VERSION ""

NS_ :

BS_:

BU_: MAHLE_Device_2 Vehicle MAHLE_Device
VAL_TABLE_ vtEv_ACTUAL_VOLTAGE 1023 "Not Available" 1022 "Error Indicator" ;
VAL_TABLE_ vtEv_8bits 254 "Error Indicator" 255 "Not Available / Not Requested" 250 "Valid Range" ;
VAL_TABLE_ vtEv_Failure_Status 1 "True" 0 "False" ;
VAL_TABLE_ vtEv_Voltage_Range 3 "Invalid" 2 "48 V product version" 1 "24 V product version" 0 "12 V Product Version" ;
VAL_TABLE_ vtEv_Speed_Values 1023 "Invalid" 0 "Motor stops (Sleep_Mode)" ;
VAL_TABLE_ Types_DM 19 "DM19" 18 "DM18" 17 "DM17" 16 "DM16" 15 "DM15" 14 "DM14" 13 "DM13" 12 "DM12" 11 "DM11" 10 "DM10" 8 "DM8" 7 "DM7" 6 "DM6" 5 "DM5" 4 "DM4" 3 "DM3" 2 "DM2" 1 "DM1" 0 "CHOOSE" ;
VAL_TABLE_ TYPE_OF_CTS 0 "CHOOSE" 255 "ABORT" 19 "EOM" 17 "PROCEED" ;
VAL_TABLE_ Priority_values 7 "SEVEN" 6 "SIX" 5 "FIVE" 4 "FOUR" 3 "THREE" 2 "TWO" 1 "ONE" 0 "ZERO" ;

BO_ 3221225472 VECTOR__INDEPENDENT_SIG_MSG: 0 Vector__XXX
 SG_ EOL_STATUS_SW_VERSION : 0|16@1+ (1,0) [0|65535] "" Vector__XXX
 SG_ EOL_STATUS_CAN_ID : 0|2@1+ (1,0) [0|3] "" Vector__XXX
 SG_ EOL_STATUS_NTC_TEMP : 0|8@1+ (1,0) [0|255] "" Vector__XXX
 SG_ EOL_STATUS_DCLINK : 0|12@1+ (1,0) [0|4095] "" Vector__XXX
 SG_ EOL_STATUS_VBAT : 0|12@1+ (1,0) [0|4095] "" Vector__XXX
 SG_ EOL_STATUS_SW_VERSION : 0|16@1+ (1,0) [0|65535] "" Vector__XXX
 SG_ EOL_STATUS_CAN_ID : 0|2@1+ (1,0) [0|3] "" Vector__XXX
 SG_ EOL_STATUS_NTC_TEMP : 0|8@1+ (1,0) [0|255] "" Vector__XXX
 SG_ EOL_STATUS_DCLINK : 0|12@1+ (1,0) [0|4095] "" Vector__XXX
 SG_ EOL_STATUS_VBAT : 0|12@1+ (1,0) [0|4095] "" Vector__XXX
 SG_ EOL_STATUS_SW_VERSION : 0|16@1+ (1,0) [0|65535] "" Vector__XXX
 SG_ EOL_STATUS_CAN_ID : 0|2@1+ (1,0) [0|3] "" Vector__XXX
 SG_ EOL_STATUS_NTC_TEMP : 0|8@1+ (1,0) [0|255] "" Vector__XXX
 SG_ EOL_STATUS_DCLINK : 0|12@1+ (1,0) [0|4095] "" Vector__XXX
 SG_ EOL_STATUS_VBAT : 0|12@1+ (1,0) [0|4095] "" Vector__XXX
 SG_ EOL_STATUS_SHUNT_C_OFFSET : 0|12@1+ (1,0) [0|4095] "" Vector__XXX
 SG_ EOL_STATUS_SHUNT_C_CURRENT : 0|12@1+ (1,0) [0|4095] "" Vector__XXX
 SG_ EOL_STATUS_SHUNT_B_OFFSET : 0|12@1+ (1,0) [0|4095] "" Vector__XXX
 SG_ EOL_STATUS_SHUNT_B_CURRENT : 0|12@1+ (1,0) [0|4095] "" Vector__XXX
 SG_ EOL_STATUS_SHUNT_C_OFFSET : 0|12@1+ (1,0) [0|4095] "" Vector__XXX
 SG_ EOL_STATUS_SHUNT_C_CURRENT : 0|12@1+ (1,0) [0|4095] "" Vector__XXX
 SG_ EOL_STATUS_SHUNT_B_OFFSET : 0|12@1+ (1,0) [0|4095] "" Vector__XXX
 SG_ EOL_STATUS_SHUNT_B_CURRENT : 0|12@1+ (1,0) [0|4095] "" Vector__XXX
 SG_ EOL_STATUS_SHUNT_C_OFFSET : 0|12@1+ (1,0) [0|4095] "" Vector__XXX
 SG_ EOL_STATUS_SHUNT_C_CURRENT : 0|12@1+ (1,0) [0|4095] "" Vector__XXX
 SG_ EOL_STATUS_SHUNT_B_OFFSET : 0|12@1+ (1,0) [0|4095] "" Vector__XXX
 SG_ EOL_STATUS_SHUNT_B_CURRENT : 0|12@1+ (1,0) [0|4095] "" Vector__XXX
 SG_ EOL_STATUS_VOLTAGE_DCLINK_CALIB : 0|16@1+ (1,0) [0|65535] "" Vector__XXX
 SG_ EOL_STATUS_VOLTAGE_VBAT_CALIB : 0|16@1+ (1,0) [0|65535] "" Vector__XXX
 SG_ EOL_STATUS_CURRENT_C_CALIB : 0|16@1+ (1,0) [0|65535] "" Vector__XXX
 SG_ EOL_STATUS_CURRENT_B_CALIB : 0|16@1+ (1,0) [0|65535] "" Vector__XXX
 SG_ EOL_STATUS_VOLTAGE_DCLINK_CALIB : 0|16@1+ (1,0) [0|65535] "" Vector__XXX
 SG_ EOL_STATUS_VOLTAGE_VBAT_CALIB : 0|16@1+ (1,0) [0|65535] "" Vector__XXX
 SG_ EOL_STATUS_CURRENT_C_CALIB : 0|16@1+ (1,0) [0|65535] "" Vector__XXX
 SG_ EOL_STATUS_CURRENT_B_CALIB : 0|16@1+ (1,0) [0|65535] "" Vector__XXX
 SG_ EOL_STATUS_VOLTAGE_DCLINK_CALIB : 0|16@1+ (1,0) [0|65535] "" Vector__XXX
 SG_ EOL_STATUS_VOLTAGE_VBAT_CALIB : 0|16@1+ (1,0) [0|65535] "" Vector__XXX
 SG_ EOL_STATUS_CURRENT_C_CALIB : 0|16@1+ (1,0) [0|65535] "" Vector__XXX
 SG_ EOL_STATUS_CURRENT_B_CALIB : 0|16@1+ (1,0) [0|65535] "" Vector__XXX
 SG_ EOL_SET_RESET_DRIVER : 0|1@1+ (1,0) [0|1] "" Vector__XXX
 SG_ EOL_SET_PH3_VOLTAGE : 0|1@1+ (1,0) [0|1] "" Vector__XXX
 SG_ EOL_SET_PH3_DUTY : 0|8@1+ (1,0) [0|100] "" Vector__XXX
 SG_ EOL_SET_PH2_VOLTAGE : 0|1@1+ (1,0) [0|1] "" Vector__XXX
 SG_ EOL_SET_PH2_DUTY : 0|8@1+ (1,0) [0|100] "" Vector__XXX
 SG_ EOL_SET_PH1_VOLTAGE : 0|1@1+ (1,0) [0|1] "" Vector__XXX
 SG_ EOL_SET_PH1_DUTY : 0|8@1+ (1,0) [0|100] "" Vector__XXX
 SG_ EOL_SET_DEVICE_SLEEP : 0|1@1+ (1,0) [0|1] "" Vector__XXX
 SG_ EOL_SET_CALIB : 0|8@1+ (1,0) [0|255] "" Vector__XXX
 SG_ EOL_SET_RESET_DRIVER : 0|1@1+ (1,0) [0|1] "" Vector__XXX
 SG_ EOL_SET_PH3_VOLTAGE : 0|1@1+ (1,0) [0|1] "" Vector__XXX
 SG_ EOL_SET_PH3_DUTY : 0|8@1+ (1,0) [0|100] "" Vector__XXX
 SG_ EOL_SET_PH2_VOLTAGE : 0|1@1+ (1,0) [0|1] "" Vector__XXX
 SG_ EOL_SET_PH2_DUTY : 0|8@1+ (1,0) [0|100] "" Vector__XXX
 SG_ EOL_SET_PH1_VOLTAGE : 0|1@1+ (1,0) [0|1] "" Vector__XXX
 SG_ EOL_SET_PH1_DUTY : 0|8@1+ (1,0) [0|100] "" Vector__XXX
 SG_ EOL_SET_DEVICE_SLEEP : 0|1@1+ (1,0) [0|1] "" Vector__XXX
 SG_ EOL_SET_CALIB : 0|8@1+ (1,0) [0|255] "" Vector__XXX
 SG_ EOL_SET_RESET_DRIVER : 0|1@1+ (1,0) [0|1] "" Vector__XXX
 SG_ EOL_SET_PH3_VOLTAGE : 0|1@1+ (1,0) [0|1] "" Vector__XXX
 SG_ EOL_SET_PH3_DUTY : 0|8@1+ (1,0) [0|100] "" Vector__XXX
 SG_ EOL_SET_PH2_VOLTAGE : 0|1@1+ (1,0) [0|1] "" Vector__XXX
 SG_ EOL_SET_PH2_DUTY : 0|8@1+ (1,0) [0|100] "" Vector__XXX
 SG_ EOL_SET_PH1_VOLTAGE : 0|1@1+ (1,0) [0|1] "" Vector__XXX
 SG_ EOL_SET_PH1_DUTY : 0|8@1+ (1,0) [0|100] "" Vector__XXX
 SG_ EOL_SET_DEVICE_SLEEP : 0|1@1+ (1,0) [0|1] "" Vector__XXX
 SG_ EOL_SET_CALIB : 0|8@1+ (1,0) [0|255] "" Vector__XXX
 SG_ EOL_STATUS_NTC_TEMP_ERROR : 0|1@1+ (1,0) [0|1] "" Vector__XXX
 SG_ EOL_STATUS_FLASH_CRC : 0|1@1+ (1,0) [0|1] "" Vector__XXX
 SG_ EOL_STATUS_CALIB : 0|4@1+ (1,0) [0|15] "" Vector__XXX
 SG_ EOL_STATUS_CURRENT_ERROR : 0|1@1+ (1,0) [0|1] "" Vector__XXX
 SG_ EOL_STATUS_VDS_OVERVOLTAGE : 0|1@1+ (1,0) [0|1] "" Vector__XXX
 SG_ EOL_STATUS_VGS_UNDERVOLTAGE : 0|1@1+ (1,0) [0|1] "" Vector__XXX
 SG_ EOL_STATUS_BOOTS_UNDERVOLTAGE : 0|1@1+ (1,0) [0|1] "" Vector__XXX
 SG_ EOL_STATUS_LOAD_FAULT : 0|1@1+ (1,0) [0|1] "" Vector__XXX
 SG_ EOL_STATUS_VIO_UNDERVOLTAGE : 0|1@1+ (1,0) [0|1] "" Vector__XXX
 SG_ EOL_STATUS_VREG_OUT_OF_RANGE : 0|1@1+ (1,0) [0|1] "" Vector__XXX
 SG_ EOL_STATUS_LOGIC_OVER_VOLTAGE : 0|1@1+ (1,0) [0|1] "" Vector__XXX
 SG_ EOL_STATUS_VBRG_OUT_OF_RANGE : 0|1@1+ (1,0) [0|1] "" Vector__XXX
 SG_ EOL_STATUS_HIGH_TEMP_WARNING : 0|1@1+ (1,0) [0|1] "" Vector__XXX
 SG_ EOL_STATUS_OVERTEMPERATURE : 0|1@1+ (1,0) [0|1] "" Vector__XXX
 SG_ EOL_STATUS_EEPROM_ERROR : 0|1@1+ (1,0) [0|1] "" Vector__XXX
 SG_ EOL_STATUS_SERIAL_ERROR : 0|1@1+ (1,0) [0|1] "" Vector__XXX
 SG_ EOL_STATUS_POWER_ON_RESET : 0|1@1+ (1,0) [0|1] "" Vector__XXX
 SG_ EOL_STATUS_STATUS_REGISTER_FLAG : 0|1@1+ (1,0) [0|1] "" Vector__XXX
 SG_ EOL_STATUS_NTC_TEMP_ERROR : 0|1@1+ (1,0) [0|1] "" Vector__XXX
 SG_ EOL_STATUS_FLASH_CRC : 0|1@1+ (1,0) [0|1] "" Vector__XXX
 SG_ EOL_STATUS_CALIB : 0|4@1+ (1,0) [0|15] "" Vector__XXX
 SG_ EOL_STATUS_CURRENT_ERROR : 0|1@1+ (1,0) [0|1] "" Vector__XXX
 SG_ EOL_STATUS_VDS_OVERVOLTAGE : 0|1@1+ (1,0) [0|1] "" Vector__XXX
 SG_ EOL_STATUS_VGS_UNDERVOLTAGE : 0|1@1+ (1,0) [0|1] "" Vector__XXX
 SG_ EOL_STATUS_BOOTS_UNDERVOLTAGE : 0|1@1+ (1,0) [0|1] "" Vector__XXX
 SG_ EOL_STATUS_LOAD_FAULT : 0|1@1+ (1,0) [0|1] "" Vector__XXX
 SG_ EOL_STATUS_VIO_UNDERVOLTAGE : 0|1@1+ (1,0) [0|1] "" Vector__XXX
 SG_ EOL_STATUS_VREG_OUT_OF_RANGE : 0|1@1+ (1,0) [0|1] "" Vector__XXX
 SG_ EOL_STATUS_LOGIC_OVER_VOLTAGE : 0|1@1+ (1,0) [0|1] "" Vector__XXX
 SG_ EOL_STATUS_VBRG_OUT_OF_RANGE : 0|1@1+ (1,0) [0|1] "" Vector__XXX
 SG_ EOL_STATUS_HIGH_TEMP_WARNING : 0|1@1+ (1,0) [0|1] "" Vector__XXX
 SG_ EOL_STATUS_OVERTEMPERATURE : 0|1@1+ (1,0) [0|1] "" Vector__XXX
 SG_ EOL_STATUS_EEPROM_ERROR : 0|1@1+ (1,0) [0|1] "" Vector__XXX
 SG_ EOL_STATUS_SERIAL_ERROR : 0|1@1+ (1,0) [0|1] "" Vector__XXX
 SG_ EOL_STATUS_POWER_ON_RESET : 0|1@1+ (1,0) [0|1] "" Vector__XXX
 SG_ EOL_STATUS_STATUS_REGISTER_FLAG : 0|1@1+ (1,0) [0|1] "" Vector__XXX
 SG_ EOL_STATUS_NTC_TEMP_ERROR : 0|1@1+ (1,0) [0|1] "" Vector__XXX
 SG_ EOL_STATUS_FLASH_CRC : 0|1@1+ (1,0) [0|1] "" Vector__XXX
 SG_ EOL_STATUS_CALIB : 0|4@1+ (1,0) [0|15] "" Vector__XXX
 SG_ EOL_STATUS_CURRENT_ERROR : 0|1@1+ (1,0) [0|1] "" Vector__XXX
 SG_ EOL_STATUS_VDS_OVERVOLTAGE : 0|1@1+ (1,0) [0|1] "" Vector__XXX
 SG_ EOL_STATUS_VGS_UNDERVOLTAGE : 0|1@1+ (1,0) [0|1] "" Vector__XXX
 SG_ EOL_STATUS_BOOTS_UNDERVOLTAGE : 0|1@1+ (1,0) [0|1] "" Vector__XXX
 SG_ EOL_STATUS_LOAD_FAULT : 0|1@1+ (1,0) [0|1] "" Vector__XXX
 SG_ EOL_STATUS_VIO_UNDERVOLTAGE : 0|1@1+ (1,0) [0|1] "" Vector__XXX
 SG_ EOL_STATUS_VREG_OUT_OF_RANGE : 0|1@1+ (1,0) [0|1] "" Vector__XXX
 SG_ EOL_STATUS_LOGIC_OVER_VOLTAGE : 0|1@1+ (1,0) [0|1] "" Vector__XXX
 SG_ EOL_STATUS_VBRG_OUT_OF_RANGE : 0|1@1+ (1,0) [0|1] "" Vector__XXX
 SG_ EOL_STATUS_HIGH_TEMP_WARNING : 0|1@1+ (1,0) [0|1] "" Vector__XXX
 SG_ EOL_STATUS_OVERTEMPERATURE : 0|1@1+ (1,0) [0|1] "" Vector__XXX
 SG_ EOL_STATUS_EEPROM_ERROR : 0|1@1+ (1,0) [0|1] "" Vector__XXX
 SG_ EOL_STATUS_SERIAL_ERROR : 0|1@1+ (1,0) [0|1] "" Vector__XXX
 SG_ EOL_STATUS_POWER_ON_RESET : 0|1@1+ (1,0) [0|1] "" Vector__XXX
 SG_ EOL_STATUS_STATUS_REGISTER_FLAG : 0|1@1+ (1,0) [0|1] "" Vector__XXX

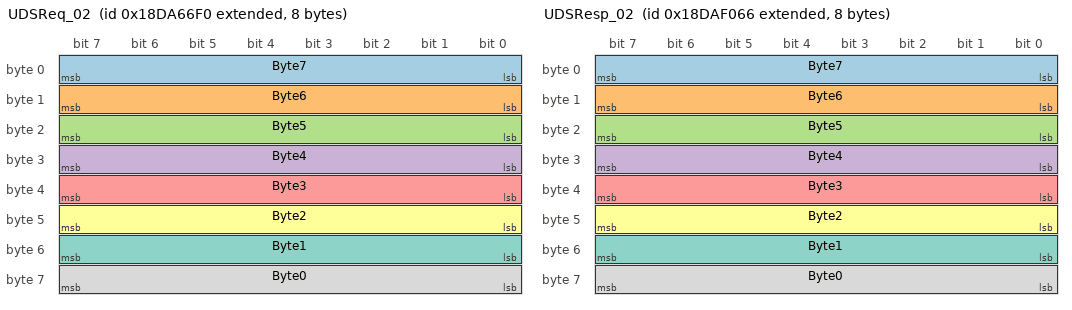
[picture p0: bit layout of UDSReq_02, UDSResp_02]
BO_ 2564450032 UDSReq_02: 8 Vehicle
 SG_ Byte7 : 7|8@0+ (1,0) [0|255] ""  MAHLE_Device_2
 SG_ Byte6 : 15|8@0+ (1,0) [0|255] ""  MAHLE_Device_2
 SG_ Byte5 : 23|8@0+ (1,0) [0|255] ""  MAHLE_Device_2
 SG_ Byte4 : 31|8@0+ (1,0) [0|255] ""  MAHLE_Device_2
 SG_ Byte3 : 39|8@0+ (1,0) [0|255] ""  MAHLE_Device_2
 SG_ Byte2 : 47|8@0+ (1,0) [0|255] ""  MAHLE_Device_2
 SG_ Byte1 : 55|8@0+ (1,0) [0|255] ""  MAHLE_Device_2
 SG_ Byte0 : 63|8@0+ (1,0) [0|255] ""  MAHLE_Device_2

BO_ 2564485222 UDSResp_02: 8 MAHLE_Device_2
 SG_ Byte7 : 7|8@0- (1,0) [0|0] "" Vector__XXX
 SG_ Byte6 : 15|8@0- (1,0) [0|0] "" Vector__XXX
 SG_ Byte5 : 23|8@0- (1,0) [0|0] "" Vector__XXX
 SG_ Byte4 : 31|8@0- (1,0) [0|0] "" Vector__XXX
 SG_ Byte3 : 39|8@0- (1,0) [0|0] "" Vector__XXX
 SG_ Byte2 : 47|8@0- (1,0) [0|0] "" Vector__XXX
 SG_ Byte1 : 55|8@0- (1,0) [0|0] "" Vector__XXX
 SG_ Byte0 : 63|8@0- (1,0) [0|0] "" Vector__XXX

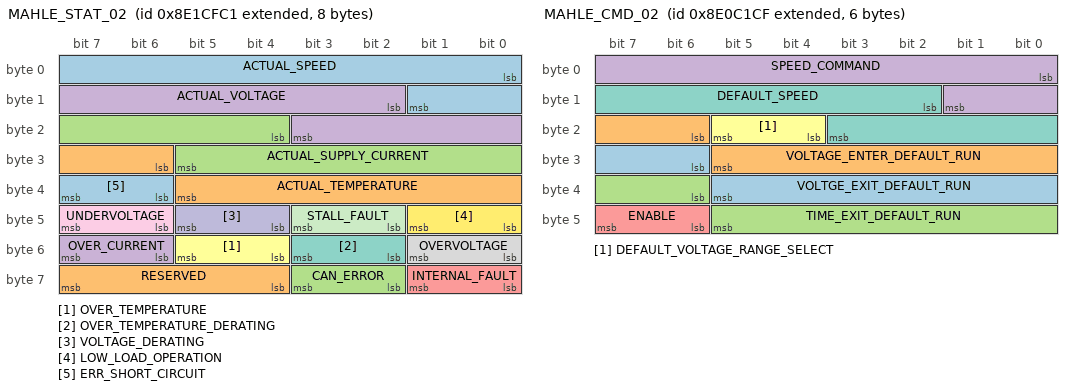
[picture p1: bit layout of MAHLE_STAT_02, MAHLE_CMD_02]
BO_ 2296500161 MAHLE_STAT_02: 8 MAHLE_Device_2
 SG_ ACTUAL_SPEED : 0|10@1+ (20,0) [0|20360] "rpm" Vector__XXX
 SG_ RESERVED : 60|4@1+ (1,0) [0|0] "" Vector__XXX
 SG_ CAN_ERROR : 58|2@1+ (1,0) [0|1] "" Vector__XXX
 SG_ OVER_CURRENT : 54|2@1+ (1,0) [0|1] "" Vector__XXX
 SG_ INTERNAL_FAULT : 56|2@1+ (1,0) [0|1] "" Vector__XXX
 SG_ OVER_TEMPERATURE : 52|2@1+ (1,0) [0|1] "" Vector__XXX
 SG_ OVER_TEMPERATURE_DERATING : 50|2@1+ (1,0) [0|1] "" Vector__XXX
 SG_ OVERVOLTAGE : 48|2@1+ (1,0) [0|1] "" Vector__XXX
 SG_ UNDERVOLTAGE : 46|2@1+ (1,0) [0|1] "" Vector__XXX
 SG_ VOLTAGE_DERATING : 44|2@1+ (1,0) [0|1] "" Vector__XXX
 SG_ STALL_FAULT : 42|2@1+ (1,0) [0|1] "" Vector__XXX
 SG_ LOW_LOAD_OPERATION : 40|2@1+ (1,0) [0|1] "" Vector__XXX
 SG_ ERR_SHORT_CIRCUIT : 38|2@1+ (1,0) [0|3] "" Vector__XXX
 SG_ ACTUAL_TEMPERATURE : 30|8@1+ (1,-50) [-50|200] "deg C" Vector__XXX
 SG_ ACTUAL_SUPPLY_CURRENT : 20|10@1+ (0.2,0) [0|204.6] "A" Vector__XXX
 SG_ ACTUAL_VOLTAGE : 10|10@1+ (0.1,0) [0|101.8] "V" Vector__XXX

BO_ 2296431055 MAHLE_CMD_02: 6 Vehicle
 SG_ VOLTGE_EXIT_DEFAULT_RUN : 30|8@1+ (0.4,17) [17|42.2] "V"  MAHLE_Device_2
 SG_ VOLTAGE_ENTER_DEFAULT_RUN : 22|8@1+ (0.4,17) [17|42.2] "V"  MAHLE_Device_2
 SG_ TIME_EXIT_DEFAULT_RUN : 38|8@1+ (10,0) [0|255] "s"  MAHLE_Device_2
 SG_ SPEED_COMMAND : 0|10@1+ (20,0) [0|20360] "rpm"  MAHLE_Device_2
 SG_ ENABLE : 46|2@1+ (1,0) [0|1] ""  MAHLE_Device_2
 SG_ DEFAULT_VOLTAGE_RANGE_SELECT : 20|2@1+ (1,0) [0|3] ""  MAHLE_Device_2
 SG_ DEFAULT_SPEED : 10|10@1+ (20,0) [0|20360] "rpm"  MAHLE_Device_2

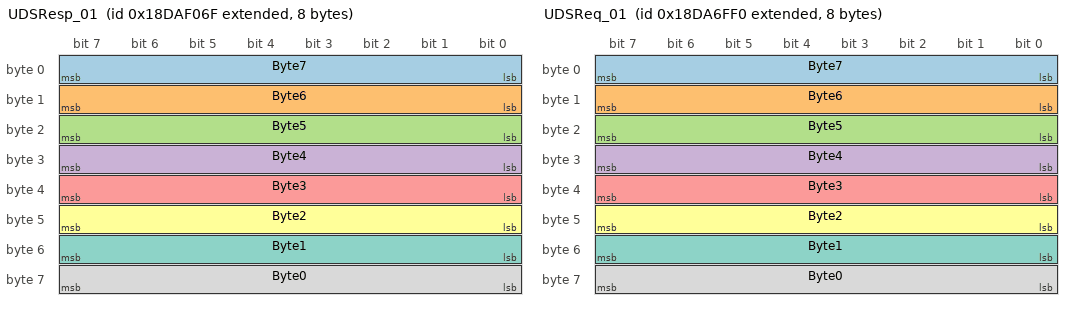
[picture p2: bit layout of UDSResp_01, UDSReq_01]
BO_ 2564485231 UDSResp_01: 8 MAHLE_Device
 SG_ Byte7 : 7|8@0- (1,0) [0|0] "" Vector__XXX
 SG_ Byte6 : 15|8@0- (1,0) [0|0] "" Vector__XXX
 SG_ Byte5 : 23|8@0- (1,0) [0|0] "" Vector__XXX
 SG_ Byte4 : 31|8@0- (1,0) [0|0] "" Vector__XXX
 SG_ Byte3 : 39|8@0- (1,0) [0|0] "" Vector__XXX
 SG_ Byte2 : 47|8@0- (1,0) [0|0] "" Vector__XXX
 SG_ Byte1 : 55|8@0- (1,0) [0|0] "" Vector__XXX
 SG_ Byte0 : 63|8@0- (1,0) [0|0] "" Vector__XXX

BO_ 2564452336 UDSReq_01: 8 Vehicle
 SG_ Byte7 : 7|8@0+ (1,0) [0|255] ""  MAHLE_Device
 SG_ Byte6 : 15|8@0+ (1,0) [0|255] ""  MAHLE_Device
 SG_ Byte5 : 23|8@0+ (1,0) [0|255] ""  MAHLE_Device
 SG_ Byte4 : 31|8@0+ (1,0) [0|255] ""  MAHLE_Device
 SG_ Byte3 : 39|8@0+ (1,0) [0|255] ""  MAHLE_Device
 SG_ Byte2 : 47|8@0+ (1,0) [0|255] ""  MAHLE_Device
 SG_ Byte1 : 55|8@0+ (1,0) [0|255] ""  MAHLE_Device
 SG_ Byte0 : 63|8@0+ (1,0) [0|255] ""  MAHLE_Device

BO_ 2600402944 NM_Range: 8 Vehicle
 SG_ NM_WakeUp2 : 32|32@1+ (1,0) [0|0] ""  MAHLE_Device_2,MAHLE_Device
 SG_ NM_WakeUp1 : 0|32@1+ (1,0) [0|4294967295] ""  MAHLE_Device,MAHLE_Device_2

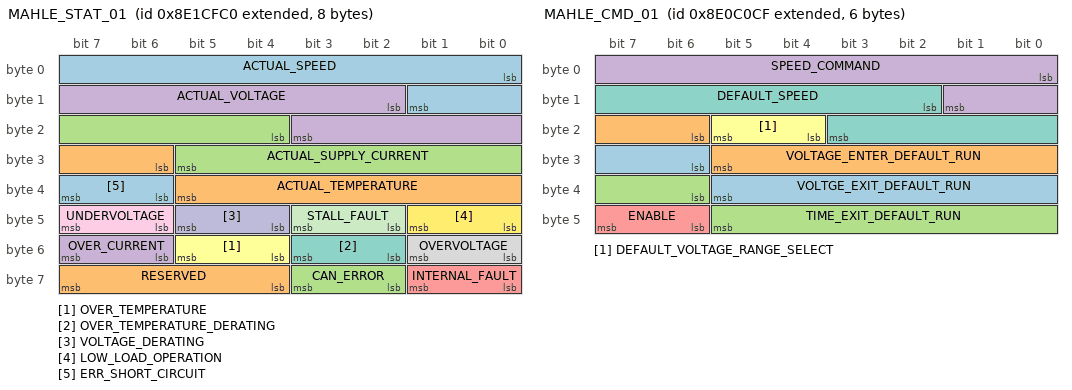
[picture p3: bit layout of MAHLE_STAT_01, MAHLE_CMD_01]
BO_ 2296500160 MAHLE_STAT_01: 8 MAHLE_Device
 SG_ ACTUAL_SPEED : 0|10@1+ (20,0) [0|20360] "rpm" Vector__XXX
 SG_ RESERVED : 60|4@1+ (1,0) [0|0] "" Vector__XXX
 SG_ CAN_ERROR : 58|2@1+ (1,0) [0|1] "" Vector__XXX
 SG_ OVER_CURRENT : 54|2@1+ (1,0) [0|1] "" Vector__XXX
 SG_ INTERNAL_FAULT : 56|2@1+ (1,0) [0|1] "" Vector__XXX
 SG_ OVER_TEMPERATURE : 52|2@1+ (1,0) [0|1] "" Vector__XXX
 SG_ OVER_TEMPERATURE_DERATING : 50|2@1+ (1,0) [0|1] "" Vector__XXX
 SG_ OVERVOLTAGE : 48|2@1+ (1,0) [0|1] "" Vector__XXX
 SG_ UNDERVOLTAGE : 46|2@1+ (1,0) [0|1] "" Vector__XXX
 SG_ VOLTAGE_DERATING : 44|2@1+ (1,0) [0|1] "" Vector__XXX
 SG_ STALL_FAULT : 42|2@1+ (1,0) [0|1] "" Vector__XXX
 SG_ LOW_LOAD_OPERATION : 40|2@1+ (1,0) [0|1] "" Vector__XXX
 SG_ ERR_SHORT_CIRCUIT : 38|2@1+ (1,0) [0|3] "" Vector__XXX
 SG_ ACTUAL_TEMPERATURE : 30|8@1+ (1,-50) [-50|200] "deg C" Vector__XXX
 SG_ ACTUAL_SUPPLY_CURRENT : 20|10@1+ (0.2,0) [0|204.6] "A" Vector__XXX
 SG_ ACTUAL_VOLTAGE : 10|10@1+ (0.1,0) [0|101.8] "V" Vector__XXX

BO_ 2296430799 MAHLE_CMD_01: 6 Vehicle
 SG_ VOLTGE_EXIT_DEFAULT_RUN : 30|8@1+ (0.4,17) [17|42.2] "V"  MAHLE_Device
 SG_ VOLTAGE_ENTER_DEFAULT_RUN : 22|8@1+ (0.4,17) [17|42.2] "V"  MAHLE_Device
 SG_ TIME_EXIT_DEFAULT_RUN : 38|8@1+ (10,0) [0|255] "s"  MAHLE_Device
 SG_ SPEED_COMMAND : 0|10@1+ (20,0) [0|20360] "rpm"  MAHLE_Device
 SG_ ENABLE : 46|2@1+ (1,0) [0|1] ""  MAHLE_Device
 SG_ DEFAULT_VOLTAGE_RANGE_SELECT : 20|2@1+ (1,0) [0|3] ""  MAHLE_Device
 SG_ DEFAULT_SPEED : 10|10@1+ (20,0) [0|20360] "rpm"  MAHLE_Device

BO_ 2430865424 EOL_Error_Status: 8 Vector__XXX
 SG_ EOL_STATUS_NTC_TEMP_ERROR : 19|1@1+ (1,0) [0|1] "" Vector__XXX
 SG_ EOL_STATUS_FLASH_CRC : 20|1@1+ (1,0) [0|1] "" Vector__XXX
 SG_ EOL_STATUS_CALIB : 15|4@1+ (1,0) [0|15] "" Vector__XXX
 SG_ EOL_STATUS_CURRENT_ERROR : 14|1@1+ (1,0) [0|1] "" Vector__XXX
 SG_ EOL_STATUS_VDS_OVERVOLTAGE : 13|1@1+ (1,0) [0|1] "" Vector__XXX
 SG_ EOL_STATUS_VGS_UNDERVOLTAGE : 12|1@1+ (1,0) [0|1] "" Vector__XXX
 SG_ EOL_STATUS_BOOTS_UNDERVOLTAGE : 11|1@1+ (1,0) [0|1] "" Vector__XXX
 SG_ EOL_STATUS_LOAD_FAULT : 10|1@1+ (1,0) [0|1] "" Vector__XXX
 SG_ EOL_STATUS_VIO_UNDERVOLTAGE : 9|1@1+ (1,0) [0|1] "" Vector__XXX
 SG_ EOL_STATUS_VREG_OUT_OF_RANGE : 8|1@1+ (1,0) [0|1] "" Vector__XXX
 SG_ EOL_STATUS_LOGIC_OVER_VOLTAGE : 7|1@1+ (1,0) [0|1] "" Vector__XXX
 SG_ EOL_STATUS_VBRG_OUT_OF_RANGE : 6|1@1+ (1,0) [0|1] "" Vector__XXX
 SG_ EOL_STATUS_HIGH_TEMP_WARNING : 5|1@1+ (1,0) [0|1] "" Vector__XXX
 SG_ EOL_STATUS_OVERTEMPERATURE : 4|1@1+ (1,0) [0|1] "" Vector__XXX
 SG_ EOL_STATUS_EEPROM_ERROR : 3|1@1+ (1,0) [0|1] "" Vector__XXX
 SG_ EOL_STATUS_SERIAL_ERROR : 2|1@1+ (1,0) [0|1] "" Vector__XXX
 SG_ EOL_STATUS_POWER_ON_RESET : 1|1@1+ (1,0) [0|1] "" Vector__XXX
 SG_ EOL_STATUS_STATUS_REGISTER_FLAG : 0|1@1+ (1,0) [0|1] "" Vector__XXX

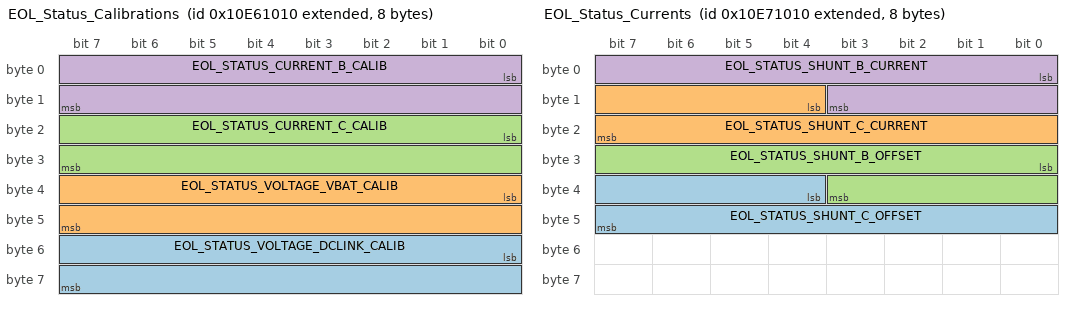
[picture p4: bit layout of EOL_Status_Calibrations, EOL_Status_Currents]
BO_ 2430996496 EOL_Status_Calibrations: 8 Vector__XXX
 SG_ EOL_STATUS_VOLTAGE_DCLINK_CALIB : 48|16@1+ (1,0) [0|65535] "" Vector__XXX
 SG_ EOL_STATUS_VOLTAGE_VBAT_CALIB : 32|16@1+ (1,0) [0|65535] "" Vector__XXX
 SG_ EOL_STATUS_CURRENT_C_CALIB : 16|16@1+ (1,0) [0|65535] "" Vector__XXX
 SG_ EOL_STATUS_CURRENT_B_CALIB : 0|16@1+ (1,0) [0|65535] "" Vector__XXX

BO_ 2431062032 EOL_Status_Currents: 8 Vector__XXX
 SG_ EOL_STATUS_SHUNT_C_OFFSET : 36|12@1+ (1,0) [0|4095] "" Vector__XXX
 SG_ EOL_STATUS_SHUNT_C_CURRENT : 12|12@1+ (0.0258288724072558,0) [0|4095] "" Vector__XXX
 SG_ EOL_STATUS_SHUNT_B_OFFSET : 24|12@1+ (1,0) [0|4095] "" Vector__XXX
 SG_ EOL_STATUS_SHUNT_B_CURRENT : 0|12@1+ (0.0258288724072558,0) [0|4095] "" Vector__XXX

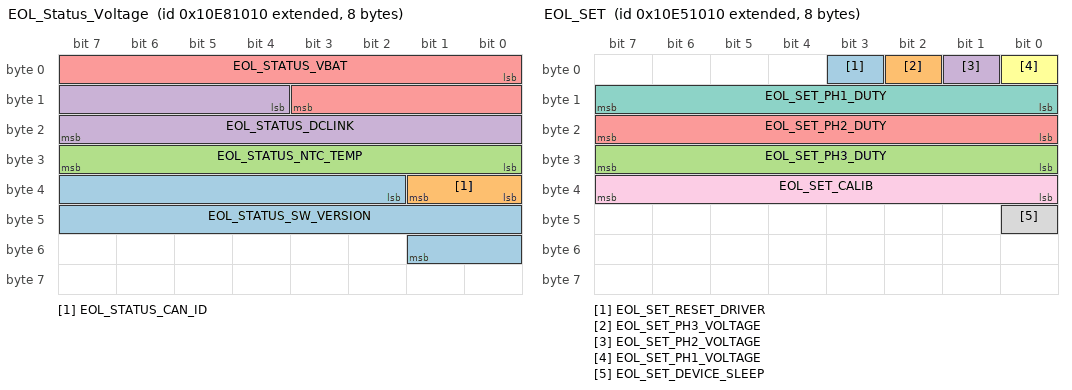
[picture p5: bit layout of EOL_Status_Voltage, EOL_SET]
BO_ 2431127568 EOL_Status_Voltage: 8 Vector__XXX
 SG_ EOL_STATUS_SW_VERSION : 34|16@1+ (1,0) [0|65535] "" Vector__XXX
 SG_ EOL_STATUS_CAN_ID : 32|2@1+ (1,0) [0|3] "" Vector__XXX
 SG_ EOL_STATUS_NTC_TEMP : 24|8@1+ (1,-50) [0|255] "" Vector__XXX
 SG_ EOL_STATUS_DCLINK : 12|12@1+ (0.0127408823060997,0) [0|4095] "" Vector__XXX
 SG_ EOL_STATUS_VBAT : 0|12@1+ (0.0127408823060997,0) [0|4095] "" Vector__XXX

BO_ 2430930960 EOL_SET: 8 Vector__XXX
 SG_ EOL_SET_RESET_DRIVER : 3|1@1+ (1,0) [0|1] ""  Vehicle
 SG_ EOL_SET_PH3_VOLTAGE : 2|1@1+ (1,0) [0|1] ""  Vehicle
 SG_ EOL_SET_PH3_DUTY : 24|8@1+ (1,0) [0|100] ""  Vehicle
 SG_ EOL_SET_PH2_VOLTAGE : 1|1@1+ (1,0) [0|1] ""  Vehicle
 SG_ EOL_SET_PH2_DUTY : 16|8@1+ (1,0) [0|100] ""  Vehicle
 SG_ EOL_SET_PH1_VOLTAGE : 0|1@1+ (1,0) [0|1] ""  Vehicle
 SG_ EOL_SET_PH1_DUTY : 8|8@1+ (1,0) [0|100] ""  Vehicle
 SG_ EOL_SET_DEVICE_SLEEP : 40|1@1+ (1,0) [0|1] ""  Vehicle
 SG_ EOL_SET_CALIB : 32|8@1+ (1,0) [0|255] ""  Vehicle

EV_ j1939_client_server: 0 [0|0] "" 0 1 DUMMY_NODE_VECTOR0 Vector__XXX;

EV_ Diag_data_to_transfer: 0 [0|0] "" 0 2 DUMMY_NODE_VECTOR8000 Vector__XXX;

EV_ Req_DM: 0 [0|0] "" 0 3 DUMMY_NODE_VECTOR0 Vector__XXX;

EV_ timer_env: 0 [0|0] "" 0 4 DUMMY_NODE_VECTOR8000 Vector__XXX;

EV_ Broadcast: 0 [0|0] "" 0 5 DUMMY_NODE_VECTOR0 Vector__XXX;

EV_ Data_to_broadcast: 0 [0|0] "" 0 6 DUMMY_NODE_VECTOR8000 Vector__XXX;

EV_ Broadcast_pgn: 0 [0|0] "" 0 7 DUMMY_NODE_VECTOR0 Vector__XXX;

EV_ Send_command: 0 [0|0] "" 0 8 DUMMY_NODE_VECTOR0 Vector__XXX;

EV_ command_PGN: 0 [0|0] "" 0 9 DUMMY_NODE_VECTOR0 Vector__XXX;

EV_ Abort_reason: 0 [0|0] "" 0 10 DUMMY_NODE_VECTOR0 Vector__XXX;

EV_ Type_of_CTS: 0 [0|0] "" 0 11 DUMMY_NODE_VECTOR0 Vector__XXX;

EV_ Num_of_packts_to_accept: 0 [0|0] "" 0 12 DUMMY_NODE_VECTOR0 Vector__XXX;

EV_ Send_TP_DATA: 0 [0|0] "" 0 13 DUMMY_NODE_VECTOR0 Vector__XXX;

EV_ send_CTS: 0 [0|0] "" 0 14 DUMMY_NODE_VECTOR0 Vector__XXX;

EV_ send_RTS: 0 [0|0] "" 0 15 DUMMY_NODE_VECTOR0 Vector__XXX;

EV_ Data_to_transfer: 0 [0|0] "" 0 16 DUMMY_NODE_VECTOR8000 Vector__XXX;

EV_ pgn_transport: 0 [0|65535] "" 0 17 DUMMY_NODE_VECTOR0 Vector__XXX;

EV_ Num_packets_per_CTS: 0 [0|0] "" 0 18 DUMMY_NODE_VECTOR0 Vector__XXX;

EV_ command_data_to_send: 0 [0|0] "" 0 19 DUMMY_NODE_VECTOR8000 Vector__XXX;

EV_ name_filed_data: 0 [0|0] "" 0 20 DUMMY_NODE_VECTOR8000 Vector__XXX;

EV_ commanded_address: 0 [0|0] "" 0 21 DUMMY_NODE_VECTOR0 Vector__XXX;

EV_ cannot_claim_address: 0 [0|0] "" 0 22 DUMMY_NODE_VECTOR0 Vector__XXX;

EV_ req_for_address_claim: 0 [0|0] "" 0 23 DUMMY_NODE_VECTOR0 Vector__XXX;

EV_ Negative_ack: 0 [0|0] "" 0 24 DUMMY_NODE_VECTOR0 Vector__XXX;

EV_ Positive_ack: 0 [0|0] "" 0 25 DUMMY_NODE_VECTOR0 Vector__XXX;

EV_ Address_claim_response: 0 [0|0] "" 0 26 DUMMY_NODE_VECTOR0 Vector__XXX;

EV_ torque_speed_ctrl: 0 [0|0] "" 0 27 DUMMY_NODE_VECTOR0 Vector__XXX;

EV_ transmission_ctrl_cmnd: 0 [0|0] "" 0 28 DUMMY_NODE_VECTOR0 Vector__XXX;

EV_ data_to_send: 0 [0|0] "" 0 29 DUMMY_NODE_VECTOR8000 Vector__XXX;

EV_ pdu_format: 0 [0|0] "" 0 30 DUMMY_NODE_VECTOR0 Vector__XXX;

EV_ requestPGN: 0 [0|0] "" 0 31 DUMMY_NODE_VECTOR0 Vector__XXX;

EV_ pgn_to_request: 0 [0|0] "" 0 32 DUMMY_NODE_VECTOR0 Vector__XXX;

EV_ requesting_pgn: 0 [0|0] "" 0 33 DUMMY_NODE_VECTOR0 Vector__XXX;

EV_ PGN_TO_REQ: 0 [0|0] "" 0 34 DUMMY_NODE_VECTOR0 Vector__XXX;

EV_ Send_Msg: 0 [0|0] "" 0 35 DUMMY_NODE_VECTOR0 Vector__XXX;

EV_ Request_BAM: 0 [0|0] "" 0 36 DUMMY_NODE_VECTOR0 Vector__XXX;

EV_ Request_PGN: 0 [0|0] "" 0 37 DUMMY_NODE_VECTOR0 Vector__XXX;

EV_ PGN: 0 [0|0] "" 0 38 DUMMY_NODE_VECTOR0 Vector__XXX;

EV_ Priority: 0 [0|0] "" 0 39 DUMMY_NODE_VECTOR0 Vector__XXX;

EV_ Source_address: 0 [0|0] "" 0 40 DUMMY_NODE_VECTOR0 Vector__XXX;

EV_ Target_Address: 0 [0|0] "" 0 41 DUMMY_NODE_VECTOR0 Vector__XXX;

CM_ BO_ 3221225472 "This is a message for not used signals, created by Vector CANdb++ DBC OLE DB Provider.";
CM_ SG_ 3221225472 EOL_STATUS_SW_VERSION "4-digit value showing software version4-digit value showing software version4-digit value showing software version";
CM_ SG_ 3221225472 EOL_STATUS_NTC_TEMP "Temperature measured on NTC resistor [°C]Temperature measured on NTC resistor [°C]Temperature measured on NTC resistor [°C]";
CM_ SG_ 3221225472 EOL_STATUS_DCLINK "DC-Link voltage [V]DC-Link voltage [V]DC-Link voltage [V]";
CM_ SG_ 3221225472 EOL_STATUS_VBAT "Battery (power supply) voltage [V]Battery (power supply) voltage [V]Battery (power supply) voltage [V]";
CM_ SG_ 3221225472 EOL_STATUS_SHUNT_C_OFFSET "12bit adc value of current measurement circuit12bit adc value of current measurement circuit12bit adc value of current measurement circuit";
CM_ SG_ 3221225472 EOL_STATUS_SHUNT_C_CURRENT "Current measured through shunt resistor [A]Current measured through shunt resistor [A]Current measured through shunt resistor [A]";
CM_ SG_ 3221225472 EOL_STATUS_SHUNT_B_OFFSET "12bit adc value of current measurement circuit12bit adc value of current measurement circuit12bit adc value of current measurement circuit";
CM_ SG_ 3221225472 EOL_STATUS_SHUNT_B_CURRENT "Current measured through shunt resistor [A]Current measured through shunt resistor [A]Current measured through shunt resistor [A]";
CM_ SG_ 3221225472 EOL_SET_RESET_DRIVER "Attention: This signal resets the ELMOS driver only on a change from 0 to 1!Attention: This signal resets the ELMOS driver only on a change from 0 to 1!Attention: This signal resets the ELMOS driver only on a change from 0 to 1!";
BA_DEF_ SG_  "SigType" ENUM  "Default","Range","RangeSigned","ASCII","Discrete","Control","ReferencePGN","DTC","StringDelimiter","StringLength","StringLengthControl","MessageCounter","MessageChecksum";
BA_DEF_ SG_  "GenSigEVName" STRING ;
BA_DEF_ SG_  "GenSigILSupport" ENUM  "No","Yes";
BA_DEF_ SG_  "GenSigSendType" ENUM  "Cyclic","OnWrite","OnWriteWithRepetition","OnChange","OnChangeWithRepetition","IfActive","IfActiveWithRepetition","NoSigSendType";
BA_DEF_ SG_  "GenSigStartValue" INT 0 2147483647;
BA_DEF_ BO_  "GenMsgILSupport" ENUM  "No","Yes";
BA_DEF_ BU_  "NmStationAddress" INT 0 255;
BA_DEF_ BO_  "GenMsgSendType" ENUM  "cyclic","NotUsed","IfActive","NotUsed","NotUsed","NotUsed","NotUsed","NotUsed","noMsgSendType";
BA_DEF_ BO_  "GenMsgRequestable" INT 0 1;
BA_DEF_ BO_  "GenMsgCycleTime" INT 0 3600000;
BA_DEF_ SG_  "SPN" INT 0 524287;
BA_DEF_  "DBName" STRING ;
BA_DEF_  "BusType" STRING ;
BA_DEF_  "ProtocolType" STRING ;
BA_DEF_ BO_  "VFrameFormat" ENUM  "StandardCAN","ExtendedCAN","reserved","J1939PG";
BA_DEF_DEF_  "SigType" "Default";
BA_DEF_DEF_  "GenSigEVName" "Env@Nodename_@Signame";
BA_DEF_DEF_  "GenSigILSupport" "Yes";
BA_DEF_DEF_  "GenSigSendType" "NoSigSendType";
BA_DEF_DEF_  "GenSigStartValue" 0;
BA_DEF_DEF_  "GenMsgILSupport" "Yes";
BA_DEF_DEF_  "NmStationAddress" 254;
BA_DEF_DEF_  "GenMsgSendType" "noMsgSendType";
BA_DEF_DEF_  "GenMsgRequestable" 1;
BA_DEF_DEF_  "GenMsgCycleTime" 0;
BA_DEF_DEF_  "SPN" 0;
BA_DEF_DEF_  "DBName" "";
BA_DEF_DEF_  "BusType" "CAN";
BA_DEF_DEF_  "ProtocolType" "J1939";
BA_DEF_DEF_  "VFrameFormat" "J1939PG";
BA_ "ProtocolType" "";
BA_ "DBName" "MAHLE_GENERIC_CAN";
BA_ "NmStationAddress" BU_ MAHLE_Device_2 193;
BA_ "NmStationAddress" BU_ Vehicle 207;
BA_ "NmStationAddress" BU_ MAHLE_Device 192;
BA_ "VFrameFormat" BO_ 2564450032 1;
BA_ "GenMsgCycleTime" BO_ 2564450032 500;
BA_ "GenMsgSendType" BO_ 2296500161 0;
BA_ "GenMsgCycleTime" BO_ 2296500161 100;
BA_ "GenMsgSendType" BO_ 2296431055 0;
BA_ "GenMsgCycleTime" BO_ 2296431055 100;
BA_ "GenMsgCycleTime" BO_ 2564452336 500;
BA_ "VFrameFormat" BO_ 2564452336 1;
BA_ "GenMsgCycleTime" BO_ 2600402944 100;
BA_ "GenMsgSendType" BO_ 2296500160 0;
BA_ "GenMsgCycleTime" BO_ 2296500160 100;
BA_ "GenMsgCycleTime" BO_ 2296430799 100;
BA_ "GenMsgSendType" BO_ 2296430799 0;
BA_ "SPN" SG_ 3221225472 EOL_STATUS_SW_VERSION 113;
BA_ "SPN" SG_ 3221225472 EOL_STATUS_CAN_ID 112;
BA_ "SPN" SG_ 3221225472 EOL_STATUS_NTC_TEMP 111;
BA_ "SPN" SG_ 3221225472 EOL_STATUS_DCLINK 110;
BA_ "SPN" SG_ 3221225472 EOL_STATUS_VBAT 109;
BA_ "SPN" SG_ 3221225472 EOL_STATUS_SHUNT_C_OFFSET 117;
BA_ "SPN" SG_ 3221225472 EOL_STATUS_SHUNT_C_CURRENT 115;
BA_ "SPN" SG_ 3221225472 EOL_STATUS_SHUNT_B_OFFSET 116;
BA_ "SPN" SG_ 3221225472 EOL_STATUS_SHUNT_B_CURRENT 114;
BA_ "SPN" SG_ 3221225472 EOL_STATUS_VOLTAGE_DCLINK_CALIB 121;
BA_ "GenSigStartValue" SG_ 3221225472 EOL_STATUS_VOLTAGE_DCLINK_CALIB 32768;
BA_ "SPN" SG_ 3221225472 EOL_STATUS_VOLTAGE_VBAT_CALIB 120;
BA_ "GenSigStartValue" SG_ 3221225472 EOL_STATUS_VOLTAGE_VBAT_CALIB 32768;
BA_ "SPN" SG_ 3221225472 EOL_STATUS_CURRENT_C_CALIB 119;
BA_ "GenSigStartValue" SG_ 3221225472 EOL_STATUS_CURRENT_C_CALIB 32768;
BA_ "SPN" SG_ 3221225472 EOL_STATUS_CURRENT_B_CALIB 118;
BA_ "GenSigStartValue" SG_ 3221225472 EOL_STATUS_CURRENT_B_CALIB 32768;
BA_ "SPN" SG_ 3221225472 EOL_SET_RESET_DRIVER 103;
BA_ "SPN" SG_ 3221225472 EOL_SET_PH3_VOLTAGE 102;
BA_ "SPN" SG_ 3221225472 EOL_SET_PH3_DUTY 106;
BA_ "SPN" SG_ 3221225472 EOL_SET_PH2_VOLTAGE 101;
BA_ "SPN" SG_ 3221225472 EOL_SET_PH2_DUTY 105;
BA_ "SPN" SG_ 3221225472 EOL_SET_PH1_VOLTAGE 100;
BA_ "SPN" SG_ 3221225472 EOL_SET_PH1_DUTY 104;
BA_ "SPN" SG_ 3221225472 EOL_SET_DEVICE_SLEEP 108;
BA_ "SPN" SG_ 3221225472 EOL_SET_CALIB 107;
BA_ "SPN" SG_ 3221225472 EOL_STATUS_NTC_TEMP_ERROR 139;
BA_ "SPN" SG_ 3221225472 EOL_STATUS_FLASH_CRC 138;
BA_ "SPN" SG_ 3221225472 EOL_STATUS_CALIB 137;
BA_ "SPN" SG_ 3221225472 EOL_STATUS_CURRENT_ERROR 136;
BA_ "SPN" SG_ 3221225472 EOL_STATUS_VDS_OVERVOLTAGE 135;
BA_ "SPN" SG_ 3221225472 EOL_STATUS_VGS_UNDERVOLTAGE 134;
BA_ "SPN" SG_ 3221225472 EOL_STATUS_BOOTS_UNDERVOLTAGE 133;
BA_ "SPN" SG_ 3221225472 EOL_STATUS_LOAD_FAULT 132;
BA_ "SPN" SG_ 3221225472 EOL_STATUS_VIO_UNDERVOLTAGE 131;
BA_ "SPN" SG_ 3221225472 EOL_STATUS_VREG_OUT_OF_RANGE 130;
BA_ "SPN" SG_ 3221225472 EOL_STATUS_LOGIC_OVER_VOLTAGE 129;
BA_ "SPN" SG_ 3221225472 EOL_STATUS_VBRG_OUT_OF_RANGE 128;
BA_ "SPN" SG_ 3221225472 EOL_STATUS_HIGH_TEMP_WARNING 127;
BA_ "SPN" SG_ 3221225472 EOL_STATUS_OVERTEMPERATURE 126;
BA_ "SPN" SG_ 3221225472 EOL_STATUS_EEPROM_ERROR 125;
BA_ "SPN" SG_ 3221225472 EOL_STATUS_SERIAL_ERROR 124;
BA_ "SPN" SG_ 3221225472 EOL_STATUS_POWER_ON_RESET 123;
BA_ "SPN" SG_ 3221225472 EOL_STATUS_STATUS_REGISTER_FLAG 122;
BA_ "GenSigStartValue" SG_ 2564450032 Byte7 3;
BA_ "GenSigStartValue" SG_ 2564450032 Byte6 34;
BA_ "GenSigStartValue" SG_ 2564450032 Byte5 253;
BA_ "GenSigStartValue" SG_ 2564450032 Byte4 1;
BA_ "SPN" SG_ 2296500161 ACTUAL_SPEED 1;
BA_ "GenSigStartValue" SG_ 2296500161 RESERVED 1;
BA_ "SPN" SG_ 2296500161 RESERVED 15;
BA_ "SPN" SG_ 2296500161 CAN_ERROR 4;
BA_ "GenSigStartValue" SG_ 2296500161 OVER_CURRENT 1;
BA_ "SPN" SG_ 2296500161 OVER_CURRENT 11;
BA_ "GenSigStartValue" SG_ 2296500161 INTERNAL_FAULT 1;
BA_ "SPN" SG_ 2296500161 INTERNAL_FAULT 9;
BA_ "GenSigStartValue" SG_ 2296500161 OVER_TEMPERATURE 1;
BA_ "SPN" SG_ 2296500161 OVER_TEMPERATURE 12;
BA_ "GenSigStartValue" SG_ 2296500161 OVER_TEMPERATURE_DERATING 1;
BA_ "SPN" SG_ 2296500161 OVER_TEMPERATURE_DERATING 13;
BA_ "GenSigStartValue" SG_ 2296500161 OVERVOLTAGE 1;
BA_ "SPN" SG_ 2296500161 OVERVOLTAGE 14;
BA_ "GenSigStartValue" SG_ 2296500161 UNDERVOLTAGE 1;
BA_ "SPN" SG_ 2296500161 UNDERVOLTAGE 27;
BA_ "GenSigStartValue" SG_ 2296500161 VOLTAGE_DERATING 1;
BA_ "SPN" SG_ 2296500161 VOLTAGE_DERATING 28;
BA_ "GenSigStartValue" SG_ 2296500161 STALL_FAULT 1;
BA_ "SPN" SG_ 2296500161 STALL_FAULT 17;
BA_ "GenSigStartValue" SG_ 2296500161 LOW_LOAD_OPERATION 1;
BA_ "SPN" SG_ 2296500161 LOW_LOAD_OPERATION 10;
BA_ "GenSigStartValue" SG_ 2296500161 ERR_SHORT_CIRCUIT 1;
BA_ "SPN" SG_ 2296500161 ERR_SHORT_CIRCUIT 8;
BA_ "SPN" SG_ 2296500161 ACTUAL_TEMPERATURE 2;
BA_ "SigType" SG_ 2296500161 ACTUAL_SUPPLY_CURRENT 1;
BA_ "SPN" SG_ 2296500161 ACTUAL_SUPPLY_CURRENT 31;
BA_ "SPN" SG_ 2296500161 ACTUAL_VOLTAGE 3;
BA_ "SPN" SG_ 2296431055 VOLTGE_EXIT_DEFAULT_RUN 30;
BA_ "SPN" SG_ 2296431055 VOLTAGE_ENTER_DEFAULT_RUN 29;
BA_ "SPN" SG_ 2296431055 TIME_EXIT_DEFAULT_RUN 26;
BA_ "SPN" SG_ 2296431055 SPEED_COMMAND 16;
BA_ "SPN" SG_ 2296431055 ENABLE 7;
BA_ "SPN" SG_ 2296431055 DEFAULT_VOLTAGE_RANGE_SELECT 6;
BA_ "GenSigStartValue" SG_ 2296431055 DEFAULT_VOLTAGE_RANGE_SELECT 1;
BA_ "SPN" SG_ 2296431055 DEFAULT_SPEED 5;
BA_ "GenSigStartValue" SG_ 2564452336 Byte7 3;
BA_ "GenSigStartValue" SG_ 2564452336 Byte6 34;
BA_ "GenSigStartValue" SG_ 2564452336 Byte5 253;
BA_ "GenSigStartValue" SG_ 2564452336 Byte4 1;
BA_ "SPN" SG_ 2296500160 ACTUAL_SPEED 1;
BA_ "GenSigStartValue" SG_ 2296500160 RESERVED 1;
BA_ "SPN" SG_ 2296500160 RESERVED 15;
BA_ "SPN" SG_ 2296500160 CAN_ERROR 4;
BA_ "GenSigStartValue" SG_ 2296500160 OVER_CURRENT 1;
BA_ "SPN" SG_ 2296500160 OVER_CURRENT 11;
BA_ "GenSigStartValue" SG_ 2296500160 INTERNAL_FAULT 1;
BA_ "SPN" SG_ 2296500160 INTERNAL_FAULT 9;
BA_ "GenSigStartValue" SG_ 2296500160 OVER_TEMPERATURE 1;
BA_ "SPN" SG_ 2296500160 OVER_TEMPERATURE 12;
BA_ "GenSigStartValue" SG_ 2296500160 OVER_TEMPERATURE_DERATING 1;
BA_ "SPN" SG_ 2296500160 OVER_TEMPERATURE_DERATING 13;
BA_ "GenSigStartValue" SG_ 2296500160 OVERVOLTAGE 1;
BA_ "SPN" SG_ 2296500160 OVERVOLTAGE 14;
BA_ "GenSigStartValue" SG_ 2296500160 UNDERVOLTAGE 1;
BA_ "SPN" SG_ 2296500160 UNDERVOLTAGE 27;
BA_ "GenSigStartValue" SG_ 2296500160 VOLTAGE_DERATING 1;
BA_ "SPN" SG_ 2296500160 VOLTAGE_DERATING 28;
BA_ "GenSigStartValue" SG_ 2296500160 STALL_FAULT 1;
BA_ "SPN" SG_ 2296500160 STALL_FAULT 17;
BA_ "GenSigStartValue" SG_ 2296500160 LOW_LOAD_OPERATION 1;
BA_ "SPN" SG_ 2296500160 LOW_LOAD_OPERATION 10;
BA_ "GenSigStartValue" SG_ 2296500160 ERR_SHORT_CIRCUIT 1;
BA_ "SPN" SG_ 2296500160 ERR_SHORT_CIRCUIT 8;
BA_ "SPN" SG_ 2296500160 ACTUAL_TEMPERATURE 2;
BA_ "SigType" SG_ 2296500160 ACTUAL_SUPPLY_CURRENT 1;
BA_ "SPN" SG_ 2296500160 ACTUAL_SUPPLY_CURRENT 31;
BA_ "SPN" SG_ 2296500160 ACTUAL_VOLTAGE 3;
BA_ "SPN" SG_ 2296430799 VOLTGE_EXIT_DEFAULT_RUN 30;
BA_ "SPN" SG_ 2296430799 VOLTAGE_ENTER_DEFAULT_RUN 29;
BA_ "SPN" SG_ 2296430799 TIME_EXIT_DEFAULT_RUN 26;
BA_ "SPN" SG_ 2296430799 SPEED_COMMAND 16;
BA_ "SPN" SG_ 2296430799 ENABLE 7;
BA_ "SPN" SG_ 2296430799 DEFAULT_VOLTAGE_RANGE_SELECT 6;
BA_ "GenSigStartValue" SG_ 2296430799 DEFAULT_VOLTAGE_RANGE_SELECT 1;
BA_ "SPN" SG_ 2296430799 DEFAULT_SPEED 5;
BA_ "SPN" SG_ 2430865424 EOL_STATUS_NTC_TEMP_ERROR 139;
BA_ "SPN" SG_ 2430865424 EOL_STATUS_FLASH_CRC 138;
BA_ "SPN" SG_ 2430865424 EOL_STATUS_CALIB 137;
BA_ "SPN" SG_ 2430865424 EOL_STATUS_CURRENT_ERROR 136;
BA_ "SPN" SG_ 2430865424 EOL_STATUS_VDS_OVERVOLTAGE 135;
BA_ "SPN" SG_ 2430865424 EOL_STATUS_VGS_UNDERVOLTAGE 134;
BA_ "SPN" SG_ 2430865424 EOL_STATUS_BOOTS_UNDERVOLTAGE 133;
BA_ "SPN" SG_ 2430865424 EOL_STATUS_LOAD_FAULT 132;
BA_ "SPN" SG_ 2430865424 EOL_STATUS_VIO_UNDERVOLTAGE 131;
BA_ "SPN" SG_ 2430865424 EOL_STATUS_VREG_OUT_OF_RANGE 130;
BA_ "SPN" SG_ 2430865424 EOL_STATUS_LOGIC_OVER_VOLTAGE 129;
BA_ "SPN" SG_ 2430865424 EOL_STATUS_VBRG_OUT_OF_RANGE 128;
BA_ "SPN" SG_ 2430865424 EOL_STATUS_HIGH_TEMP_WARNING 127;
BA_ "SPN" SG_ 2430865424 EOL_STATUS_OVERTEMPERATURE 126;
BA_ "SPN" SG_ 2430865424 EOL_STATUS_EEPROM_ERROR 125;
BA_ "SPN" SG_ 2430865424 EOL_STATUS_SERIAL_ERROR 124;
BA_ "SPN" SG_ 2430865424 EOL_STATUS_POWER_ON_RESET 123;
BA_ "SPN" SG_ 2430865424 EOL_STATUS_STATUS_REGISTER_FLAG 122;
BA_ "SPN" SG_ 2430996496 EOL_STATUS_VOLTAGE_DCLINK_CALIB 121;
BA_ "GenSigStartValue" SG_ 2430996496 EOL_STATUS_VOLTAGE_DCLINK_CALIB 32768;
BA_ "SPN" SG_ 2430996496 EOL_STATUS_VOLTAGE_VBAT_CALIB 120;
BA_ "GenSigStartValue" SG_ 2430996496 EOL_STATUS_VOLTAGE_VBAT_CALIB 32768;
BA_ "SPN" SG_ 2430996496 EOL_STATUS_CURRENT_C_CALIB 119;
BA_ "GenSigStartValue" SG_ 2430996496 EOL_STATUS_CURRENT_C_CALIB 32768;
BA_ "SPN" SG_ 2430996496 EOL_STATUS_CURRENT_B_CALIB 118;
BA_ "GenSigStartValue" SG_ 2430996496 EOL_STATUS_CURRENT_B_CALIB 32768;
BA_ "SPN" SG_ 2431062032 EOL_STATUS_SHUNT_C_OFFSET 117;
BA_ "SPN" SG_ 2431062032 EOL_STATUS_SHUNT_C_CURRENT 115;
BA_ "SPN" SG_ 2431062032 EOL_STATUS_SHUNT_B_OFFSET 116;
BA_ "SPN" SG_ 2431062032 EOL_STATUS_SHUNT_B_CURRENT 114;
BA_ "SPN" SG_ 2431127568 EOL_STATUS_SW_VERSION 113;
BA_ "SPN" SG_ 2431127568 EOL_STATUS_CAN_ID 112;
BA_ "SPN" SG_ 2431127568 EOL_STATUS_NTC_TEMP 111;
BA_ "GenSigStartValue" SG_ 2431127568 EOL_STATUS_NTC_TEMP 50;
BA_ "SPN" SG_ 2431127568 EOL_STATUS_DCLINK 110;
BA_ "SPN" SG_ 2431127568 EOL_STATUS_VBAT 109;
BA_ "SPN" SG_ 2430930960 EOL_SET_RESET_DRIVER 103;
BA_ "SPN" SG_ 2430930960 EOL_SET_PH3_VOLTAGE 102;
BA_ "SPN" SG_ 2430930960 EOL_SET_PH3_DUTY 106;
BA_ "SPN" SG_ 2430930960 EOL_SET_PH2_VOLTAGE 101;
BA_ "SPN" SG_ 2430930960 EOL_SET_PH2_DUTY 105;
BA_ "SPN" SG_ 2430930960 EOL_SET_PH1_VOLTAGE 100;
BA_ "SPN" SG_ 2430930960 EOL_SET_PH1_DUTY 104;
BA_ "SPN" SG_ 2430930960 EOL_SET_DEVICE_SLEEP 108;
BA_ "SPN" SG_ 2430930960 EOL_SET_CALIB 107;
VAL_ 3221225472 EOL_STATUS_CAN_ID 3 "Error (AD value not valid)" 2 "Addressing pins closed" 1 "Addressing pins open" 0 "Invalid " ;
VAL_ 3221225472 EOL_SET_PH3_VOLTAGE 1 "enabled" 0 "disabled" ;
VAL_ 3221225472 EOL_SET_PH2_VOLTAGE 1 "enabled" 0 "disabled" ;
VAL_ 3221225472 EOL_SET_PH1_VOLTAGE 1 "enabled" 0 "disabled" ;
VAL_ 3221225472 EOL_SET_DEVICE_SLEEP 1 "Sleep" 0 "Awake" ;
VAL_ 3221225472 EOL_SET_CALIB 7 "Reset calibration" 3 "Enabled Phase C calibration" 2 "Enabled Phase B calibration" 1 "Enable voltage calibration" 0 "Disabled" ;
VAL_ 3221225472 EOL_STATUS_NTC_TEMP_ERROR 1 "Temp measurement error detected" 0 "OK" ;
VAL_ 3221225472 EOL_STATUS_FLASH_CRC 1 "Flash CRC error detected" 0 " OK" ;
VAL_ 3221225472 EOL_STATUS_CALIB 15 "Step not yet executed" 5 "Volt calibration DCLINK failed" 4 "Voltage calibration VBAT failed" 3 "Current calibration PH C failed" 2 "Current calibration PH B failed" 0 "Ok" ;
VAL_ 3221225472 EOL_STATUS_CURRENT_ERROR 1 "Current measure error detected" 0 "Ok" ;
VAL_ 3221225472 EOL_STATUS_VDS_OVERVOLTAGE 1 "VDS overvoltage(DSO) detected" 0 "Ok" ;
VAL_ 3221225472 EOL_STATUS_VGS_UNDERVOLTAGE 1 "VGS undervoltage(GSU) detected" 0 "Ok" ;
VAL_ 3221225472 EOL_STATUS_BOOTS_UNDERVOLTAGE 1 "Bootstrap undervolt(BSU)detected" 0 "Ok" ;
VAL_ 3221225472 EOL_STATUS_LOAD_FAULT 1 "Load fault(LDF) detected" 0 "Ok" ;
VAL_ 3221225472 EOL_STATUS_VIO_UNDERVOLTAGE 1 "VIO undervoltage(VLU) detected" 0 "Ok" ;
VAL_ 3221225472 EOL_STATUS_VREG_OUT_OF_RANGE 1 "VREG out of range(VR) detected" 0 "Ok" ;
VAL_ 3221225472 EOL_STATUS_LOGIC_OVER_VOLTAGE 1 "Logic overvoltage(VLO) detected" 0 "Ok" ;
VAL_ 3221225472 EOL_STATUS_VBRG_OUT_OF_RANGE 1 "VBRG out of range(VS) detected" 0 "Ok" ;
VAL_ 3221225472 EOL_STATUS_HIGH_TEMP_WARNING 1 "High temp warning(TW) detected" 0 "Ok" ;
VAL_ 3221225472 EOL_STATUS_OVERTEMPERATURE 1 "Overtemperature(OT) detected " 0 "OK" ;
VAL_ 3221225472 EOL_STATUS_EEPROM_ERROR 1 "EEPROM(EE) error detected" 0 "Ok" ;
VAL_ 3221225472 EOL_STATUS_SERIAL_ERROR 1 "Serial error(SE) detected" 0 "OK" ;
VAL_ 3221225472 EOL_STATUS_POWER_ON_RESET 1 "Power on reset detected" 0 "OK" ;
VAL_ 3221225472 EOL_STATUS_STATUS_REGISTER_FLAG 1 "Status register flag(FF)detected" 0 "OK" ;
VAL_ 2296500161 ACTUAL_SPEED 1018 "Invalid" 0 "Motor stops (Sleep_Mode)" ;
VAL_ 2296500161 CAN_ERROR 1 "True" 0 "False" ;
VAL_ 2296500161 OVER_CURRENT 1 "True" 0 "False" ;
VAL_ 2296500161 INTERNAL_FAULT 1 "True" 0 "False" ;
VAL_ 2296500161 OVER_TEMPERATURE 1 "True" 0 "False" ;
VAL_ 2296500161 OVER_TEMPERATURE_DERATING 1 "True" 0 "False" ;
VAL_ 2296500161 OVERVOLTAGE 1 "True" 0 "False" ;
VAL_ 2296500161 UNDERVOLTAGE 1 "True" 0 "False" ;
VAL_ 2296500161 VOLTAGE_DERATING 1 "True" 0 "False" ;
VAL_ 2296500161 STALL_FAULT 1 "True" 0 "False" ;
VAL_ 2296500161 LOW_LOAD_OPERATION 1 "True" 0 "False" ;
VAL_ 2296500161 ERR_SHORT_CIRCUIT 1 "True" 0 "False" ;
VAL_ 2296500161 ACTUAL_TEMPERATURE 255 "Not Available" 254 "Error Indicator" ;
VAL_ 2296500161 ACTUAL_VOLTAGE 1023 "Not Available" 1022 "Error Indicator" ;
VAL_ 2296431055 TIME_EXIT_DEFAULT_RUN 254 "Error Indicator" 255 "Not Available / Not Requested" 250 "Valid Range" ;
VAL_ 2296431055 SPEED_COMMAND 1023 "Invalid" 0 "Motor stops (Sleep_Mode)" ;
VAL_ 2296431055 ENABLE 1 "True" 0 "False" ;
VAL_ 2296431055 DEFAULT_VOLTAGE_RANGE_SELECT 3 "Invalid" 2 "48 V product version" 1 "24 V product version" 0 "12 V Product Version" ;
VAL_ 2296431055 DEFAULT_SPEED 1018 "Invalid" 0 "Motor stops (Sleep_Mode)" ;
VAL_ 2296500160 ACTUAL_SPEED 1018 "Invalid" 0 "Motor stops (Sleep_Mode)" ;
VAL_ 2296500160 CAN_ERROR 1 "True" 0 "False" ;
VAL_ 2296500160 OVER_CURRENT 1 "True" 0 "False" ;
VAL_ 2296500160 INTERNAL_FAULT 1 "True" 0 "False" ;
VAL_ 2296500160 OVER_TEMPERATURE 1 "True" 0 "False" ;
VAL_ 2296500160 OVER_TEMPERATURE_DERATING 1 "True" 0 "False" ;
VAL_ 2296500160 OVERVOLTAGE 1 "True" 0 "False" ;
VAL_ 2296500160 UNDERVOLTAGE 1 "True" 0 "False" ;
VAL_ 2296500160 VOLTAGE_DERATING 1 "True" 0 "False" ;
VAL_ 2296500160 STALL_FAULT 1 "True" 0 "False" ;
VAL_ 2296500160 LOW_LOAD_OPERATION 1 "True" 0 "False" ;
VAL_ 2296500160 ERR_SHORT_CIRCUIT 1 "True" 0 "False" ;
VAL_ 2296500160 ACTUAL_TEMPERATURE 255 "Not Available" 254 "Error Indicator" ;
VAL_ 2296500160 ACTUAL_VOLTAGE 1023 "Not Available" 1022 "Error Indicator" ;
VAL_ 2296430799 TIME_EXIT_DEFAULT_RUN 254 "Error Indicator" 255 "Not Available / Not Requested" 250 "Valid Range" ;
VAL_ 2296430799 SPEED_COMMAND 1023 "Invalid" 0 "Motor stops (Sleep_Mode)" ;
VAL_ 2296430799 ENABLE 1 "True" 0 "False" ;
VAL_ 2296430799 DEFAULT_VOLTAGE_RANGE_SELECT 3 "Invalid" 2 "48 V product version" 1 "24 V product version" 0 "12 V Product Version" ;
VAL_ 2296430799 DEFAULT_SPEED 1018 "Invalid" 0 "Motor stops (Sleep_Mode)" ;
VAL_ 2430865424 EOL_STATUS_NTC_TEMP_ERROR 1 "Temp measurement error detected" 0 "OK" ;
VAL_ 2430865424 EOL_STATUS_FLASH_CRC 1 "Flash CRC error detected" 0 " OK" ;
VAL_ 2430865424 EOL_STATUS_CALIB 15 "Step not yet executed" 5 "Volt calibration DCLINK failed" 4 "Voltage calibration VBAT failed" 3 "Current calibration PH C failed" 2 "Current calibration PH B failed" 0 "Ok" ;
VAL_ 2430865424 EOL_STATUS_CURRENT_ERROR 1 "Current measure error detected" 0 "Ok" ;
VAL_ 2430865424 EOL_STATUS_VDS_OVERVOLTAGE 1 "VDS overvoltage(DSO) detected" 0 "Ok" ;
VAL_ 2430865424 EOL_STATUS_VGS_UNDERVOLTAGE 1 "VGS undervoltage(GSU) detected" 0 "Ok" ;
VAL_ 2430865424 EOL_STATUS_BOOTS_UNDERVOLTAGE 1 "Bootstrap undervolt(BSU)detected" 0 "Ok" ;
VAL_ 2430865424 EOL_STATUS_LOAD_FAULT 1 "Load fault(LDF) detected" 0 "Ok" ;
VAL_ 2430865424 EOL_STATUS_VIO_UNDERVOLTAGE 1 "VIO undervoltage(VLU) detected" 0 "Ok" ;
VAL_ 2430865424 EOL_STATUS_VREG_OUT_OF_RANGE 1 "VREG out of range(VR) detected" 0 "Ok" ;
VAL_ 2430865424 EOL_STATUS_LOGIC_OVER_VOLTAGE 1 "Logic overvoltage(VLO) detected" 0 "Ok" ;
VAL_ 2430865424 EOL_STATUS_VBRG_OUT_OF_RANGE 1 "VBRG out of range(VS) detected" 0 "Ok" ;
VAL_ 2430865424 EOL_STATUS_HIGH_TEMP_WARNING 1 "High temp warning(TW) detected" 0 "Ok" ;
VAL_ 2430865424 EOL_STATUS_OVERTEMPERATURE 1 "Overtemperature(OT) detected " 0 "OK" ;
VAL_ 2430865424 EOL_STATUS_EEPROM_ERROR 1 "EEPROM(EE) error detected" 0 "Ok" ;
VAL_ 2430865424 EOL_STATUS_SERIAL_ERROR 1 "Serial error(SE) detected" 0 "OK" ;
VAL_ 2430865424 EOL_STATUS_POWER_ON_RESET 1 "Power on reset detected" 0 "OK" ;
VAL_ 2430865424 EOL_STATUS_STATUS_REGISTER_FLAG 1 "Status register flag(FF)detected" 0 "OK" ;
VAL_ 2431127568 EOL_STATUS_CAN_ID 3 "Error (AD value not valid)" 2 "Addressing pins closed" 1 "Addressing pins open" 0 "Invalid " ;
VAL_ 2430930960 EOL_SET_PH3_VOLTAGE 1 "enabled" 0 "disabled" ;
VAL_ 2430930960 EOL_SET_PH2_VOLTAGE 1 "enabled" 0 "disabled" ;
VAL_ 2430930960 EOL_SET_PH1_VOLTAGE 1 "enabled" 0 "disabled" ;
VAL_ 2430930960 EOL_SET_DEVICE_SLEEP 1 "Sleep" 0 "Awake" ;
VAL_ 2430930960 EOL_SET_CALIB 7 "Reset calibration" 3 "Enabled Phase C calibration" 2 "Enabled Phase B calibration" 1 "Enable voltage calibration" 0 "Disabled" ;
VAL_ Req_DM 19 "DM19" 18 "DM18" 17 "DM17" 16 "DM16" 15 "DM15" 14 "DM14" 13 "DM13" 12 "DM12" 11 "DM11" 10 "DM10" 8 "DM8" 7 "DM7" 6 "DM6" 5 "DM5" 4 "DM4" 3 "DM3" 2 "DM2" 1 "DM1" 0 "CHOOSE" ;
VAL_ Type_of_CTS 0 "CHOOSE" 255 "ABORT" 19 "EOM" 17 "PROCEED" ;
VAL_ Priority 7 "SEVEN" 6 "SIX" 5 "FIVE" 4 "FOUR" 3 "THREE" 2 "TWO" 1 "ONE" 0 "ZERO" ;
